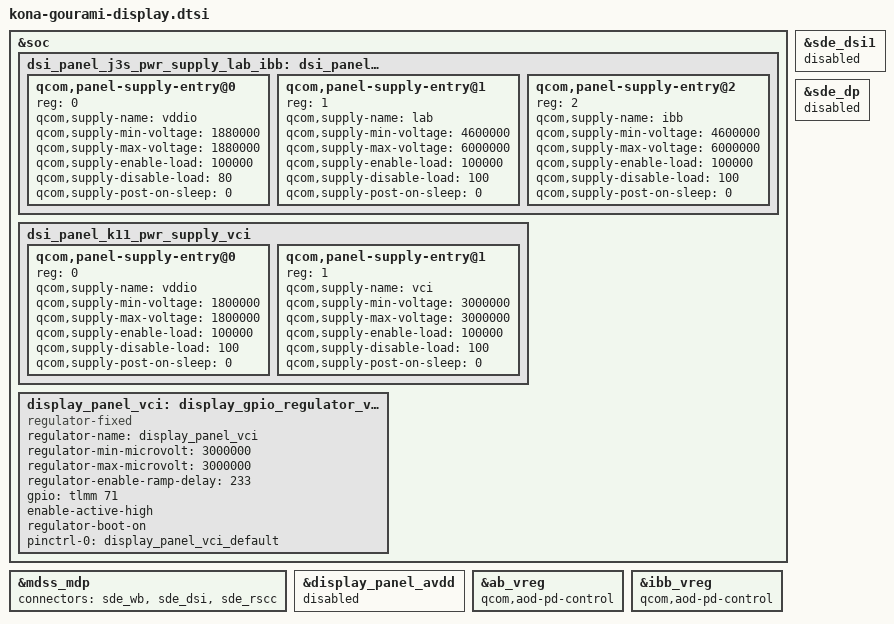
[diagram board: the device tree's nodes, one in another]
// SPDX-License-Identifier: GPL-2.0
/* Copyright (c) 2022, The Linux Foundation. All rights reserved.
 *
 * This program is free software; you can redistribute it and/or modify
 * it under the terms of the GNU General Public License version 2 and
 * only version 2 as published by the Free Software Foundation.
 *
 * This program is distributed in the hope that it will be useful,
 * but WITHOUT ANY WARRANTY; without even the implied warranty of
 * MERCHANTABILITY or FITNESS FOR A PARTICULAR PURPOSE.  See the
 * GNU General Public License for more details.
 */

#include "qcom-base/kona-sde-display.dtsi"

&soc {
	dsi_panel_j3s_pwr_supply_lab_ibb: dsi_panel_pwr_supply_lab_ibb {
		#address-cells = <1>;
		#size-cells = <0>;

		qcom,panel-supply-entry@0 {
			reg = <0>;
			qcom,supply-name = "vddio";
			qcom,supply-min-voltage = <1880000>;
			qcom,supply-max-voltage = <1880000>;
			qcom,supply-enable-load = <100000>;
			qcom,supply-disable-load = <80>;
			qcom,supply-post-on-sleep = <0>;
		};

		qcom,panel-supply-entry@1 {
			reg = <1>;
			qcom,supply-name = "lab";
			qcom,supply-min-voltage = <4600000>;
			qcom,supply-max-voltage = <6000000>;
			qcom,supply-enable-load = <100000>;
			qcom,supply-disable-load = <100>;
			qcom,supply-post-on-sleep = <0>;
		};

		qcom,panel-supply-entry@2 {
			reg = <2>;
			qcom,supply-name = "ibb";
			qcom,supply-min-voltage = <4600000>;
			qcom,supply-max-voltage = <6000000>;
			qcom,supply-enable-load = <100000>;
			qcom,supply-disable-load = <100>;
			qcom,supply-post-on-sleep = <0>;
		};
	};

	dsi_panel_k11_pwr_supply_vci: dsi_panel_k11_pwr_supply_vci {
		#address-cells = <1>;
		#size-cells = <0>;

		qcom,panel-supply-entry@0 {
			reg = <0>;
			qcom,supply-name = "vddio";
			qcom,supply-min-voltage = <1800000>;
			qcom,supply-max-voltage = <1800000>;
			qcom,supply-enable-load = <100000>;
			qcom,supply-disable-load = <100>;
			qcom,supply-post-on-sleep = <0>;
		};

		qcom,panel-supply-entry@1 {
			reg = <1>;
			qcom,supply-name = "vci";
			qcom,supply-min-voltage = <3000000>;
			qcom,supply-max-voltage = <3000000>;
			qcom,supply-enable-load = <100000>;
			qcom,supply-disable-load = <100>;
			qcom,supply-post-on-sleep = <0>;
		};
	};

	display_panel_vci: display_gpio_regulator_vci {
		compatible = "regulator-fixed";
		regulator-name = "display_panel_vci";
		regulator-min-microvolt = <3000000>;
		regulator-max-microvolt = <3000000>;
		regulator-enable-ramp-delay = <233>;
		gpio = <&tlmm 71 0>;
		enable-active-high;
		regulator-boot-on;
		pinctrl-names = "default";
		pinctrl-0 = <&display_panel_vci_default>;
	};
};

&mdss_mdp {
	connectors = <&sde_wb &sde_dsi &sde_rscc>;
};

&display_panel_avdd {
	status = "disabled";
};

&sde_dsi1 {
	status = "disabled";
};

&sde_dp {
	status = "disabled";
};

&ab_vreg {
	qcom,aod-pd-control;
};

&ibb_vreg {
	qcom,aod-pd-control;
};
